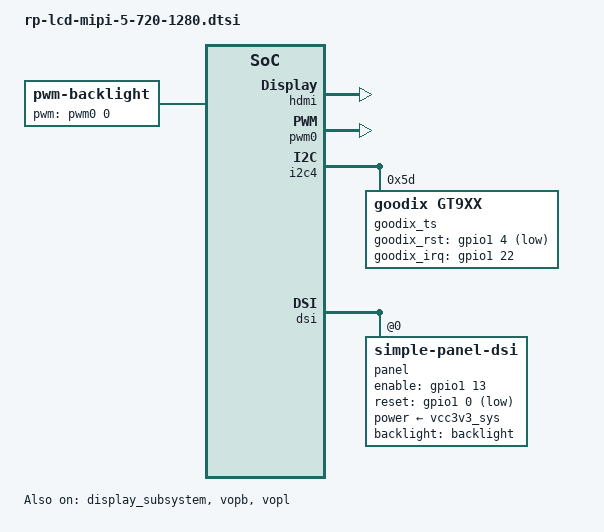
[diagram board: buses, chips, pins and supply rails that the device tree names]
/ {
	backlight: backlight {
		status = "okay";
		compatible = "pwm-backlight";
		pwms = <&pwm0 0 25000 0>;
		brightness-levels = <
			  0   1   2   3   4   5   6   7
			  8   9  10  11  12  13  14  15
			 16  17  18  19  20  21  22  23
			 24  25  26  27  28  29  30  31
			 32  33  34  35  36  37  38  39
			 40  41  42  43  44  45  46  47
			 48  49  50  51  52  53  54  55
			 56  57  58  59  60  61  62  63
			 64  65  66  67  68  69  70  71
			 72  73  74  75  76  77  78  79
			 80  81  82  83  84  85  86  87
			 88  89  90  91  92  93  94  95
			 96  97  98  99 100 101 102 103
			104 105 106 107 108 109 110 111
			112 113 114 115 116 117 118 119
			120 121 122 123 124 125 126 127
			128 129 130 131 132 133 134 135
			136 137 138 139 140 141 142 143
			144 145 146 147 148 149 150 151
			152 153 154 155 156 157 158 159
			160 161 162 163 164 165 166 167
			168 169 170 171 172 173 174 175
			176 177 178 179 180 181 182 183
			184 185 186 187 188 189 190 191
			192 193 194 195 196 197 198 199
			200 201 202 203 204 205 206 207
			208 209 210 211 212 213 214 215
			216 217 218 219 220 221 222 223
			224 225 226 227 228 229 230 231
			232 233 234 235 236 237 238 239
			240 241 242 243 244 245 246 247
			248 249 250 251 252 253 254 255>;
		default-brightness-level = <255>;
	};
};


&hdmi {
	#address-cells = <1>;
	#size-cells = <0>;
	#sound-dai-cells = <0>;
	ddc-i2c-scl-high-time-ns = <9625>;
	ddc-i2c-scl-low-time-ns = <10000>;
	status = "okay";
};

&pwm0 {
	status = "okay";
};

&i2c4 {
        status = "okay";
	goodix_ts@5d {
		compatible = "goodix,gt9xx";
		reg = <0x5d>;
		
		goodix_rst_gpio = <&gpio1 4 GPIO_ACTIVE_LOW>;
		goodix_irq_gpio = <&gpio1 22 IRQ_TYPE_EDGE_RISING>;
	
	        goodix,cfg-group0 = [
	                46 D0 02 00 05 05 35 01 01 08 1E 0F 5A 3C
	                03 05 00 00 00 00 11 11 00 19 1B 1E 14 89
	                29 0A 41 43 D3 07 00 00 00 9A 02 11 00 01
	                05 00 00 00 00 09 11 00 00 36 4A 94 45 00
	                00 00 00 00 94 37 00 8B 3B 00 83 3F 00 7C
	                43 00 76 47 00 76 10 30 48 00 F0 4A 3A FF
	                FF 27 00 00 00 00 00 00 00 00 00 00 00 00
	                00 00 00 00 00 00 00 00 00 00 00 00 00 00
	                08 0A 0C 0E 10 12 14 16 18 1A 00 00 00 00
	                00 00 00 00 00 00 00 00 00 00 00 00 00 00
	                00 00 0E 0C 0A 08 06 05 04 02 00 1D 1E 1F
	                20 22 24 28 29 2A 00 00 00 00 00 00 00 00
	                00 00 00 00 00 00 00 00 00 00 00 00 00 00
	                00 00 84 01];	
	        goodix,cfg-group1 = [
	                46 D0 02 00 05 05 35 01 01 08 1E 0F 5A 3C
	                03 05 00 00 00 00 11 11 00 19 1B 1E 14 89
	                29 0A 41 43 D3 07 00 00 00 9A 02 11 00 01
	                05 00 00 00 00 09 11 00 00 36 4A 94 45 00
	                00 00 00 00 94 37 00 8B 3B 00 83 3F 00 7C
	                43 00 76 47 00 76 10 30 48 00 F0 4A 3A FF
	                FF 27 00 00 00 00 00 00 00 00 00 00 00 00
	                00 00 00 00 00 00 00 00 00 00 00 00 00 00
	                08 0A 0C 0E 10 12 14 16 18 1A 00 00 00 00
	                00 00 00 00 00 00 00 00 00 00 00 00 00 00
	                00 00 0E 0C 0A 08 06 05 04 02 00 1D 1E 1F
	                20 22 24 28 29 2A 00 00 00 00 00 00 00 00
	                00 00 00 00 00 00 00 00 00 00 00 00 00 00
	                00 00 84 01];	
	};
};


&display_subsystem {
	status = "okay";

	ports = <&vopb_out>, <&vopl_out>;
	logo-memory-region = <&drm_logo>;

	route {
		route_hdmi: route-hdmi {
			status = "disabled";
			logo,uboot = "logo.bmp";
			logo,kernel = "logo_kernel.bmp";
			logo,mode = "fullscreen";
			charge_logo,mode = "center";
			connect = <&vopl_out_hdmi>;
		};

		route_dsi: route-dsi {
			status = "okay";
			logo,uboot = "logo.bmp";
			logo,kernel = "logo_kernel.bmp";
			logo,mode = "fullscreen";
			charge_logo,mode = "center";
			connect = <&vopb_out_dsi>;
		};

		route_dsi1: route-dsi1 {
			status = "disabled";
			logo,uboot = "logo.bmp";
			logo,kernel = "logo_kernel.bmp";
			logo,mode = "fullscreen";
			charge_logo,mode = "center";
			connect = <&vopl_out_dsi1>;
		};

		route_edp: route-edp {
			status = "disabled";
			logo,uboot = "logo.bmp";
			logo,kernel = "logo_kernel.bmp";
			logo,mode = "fullscreen";
			charge_logo,mode = "center";
			connect = <&vopb_out_edp>;
		};
	};
};

&dsi {
        status = "okay";
//	rockchip,lane-rate = <410>;

        panel {
                compatible ="simple-panel-dsi";
                status = "okay";
                reg = <0>;
		power-supply = <&vcc3v3_sys>;
                backlight = <&backlight>;
		cmd_later_reset = <0>;
                enable-gpios = <&gpio1 13 GPIO_ACTIVE_HIGH>;
		reset-gpios  = <&gpio1 0 GPIO_ACTIVE_LOW>;
                dsi,flags = <(MIPI_DSI_MODE_VIDEO | MIPI_DSI_MODE_VIDEO_BURST |
                                MIPI_DSI_MODE_VIDEO_SYNC_PULSE)>;
                dsi,format = <MIPI_DSI_FMT_RGB888>;
//		bus-format = <MEDIA_BUS_FMT_RGB666_1X24>;
                dsi,lanes = <4>;
                reset-delay-ms = <20>;
		init-delay-ms = <20>;
		enable-delay-ms = <120>;
                prepare-delay-ms = <120>;

					//for king/rp/rd board cannot enable boot logo
                                        pinctrl-names = "default";
                                        pinctrl-0 = <&pwr_en>;
               panel-init-sequence = [
			39 00 02 FE 01
			39 00 02 24 00
			39 00 02 25 53
			39 00 02 26 00
			39 00 02 27 0A
			39 00 02 29 0A
			39 00 02 2B E5
			39 00 02 16 52
			39 00 02 2F 54
			39 00 02 34 59
			39 00 02 1B 50
			39 00 02 12 02
			39 00 02 1A 06
			39 00 02 46 5F
			39 00 02 52 70
			39 00 02 53 00
			39 00 02 54 70
			39 00 02 55 00
			39 00 02 5F 13
			39 00 02 FE 03
			39 00 02 00 05
			39 00 02 01 16
			39 00 02 02 0B
			39 00 02 03 0F
			39 00 02 04 7D
			39 00 02 05 00
			39 00 02 06 50
			39 00 02 07 05
			39 00 02 08 16
			39 00 02 09 0D
			39 00 02 0A 11
			39 00 02 0B 7D
			39 00 02 0C 00
			39 00 02 0D 50
			39 00 02 0E 07
			39 00 02 0F 08
			39 00 02 10 01
			39 00 02 11 02
			39 00 02 12 00
			39 00 02 13 7D
			39 00 02 14 00
			39 00 02 15 85
			39 00 02 16 08
			39 00 02 17 03
			39 00 02 18 04
			39 00 02 19 05
			39 00 02 1A 06
			39 00 02 1B 00
			39 00 02 1C 7D
			39 00 02 1D 00
			39 00 02 1E 85
			39 00 02 1F 08
			39 00 02 20 00
			39 00 02 21 00
			39 00 02 22 00
			39 00 02 23 00
			39 00 02 24 00
			39 00 02 25 00
			39 00 02 26 00
			39 00 02 27 00
			39 00 02 28 00
			39 00 02 29 00
			39 00 02 2A 07
			39 00 02 2B 08
			39 00 02 2D 01
			39 00 02 2F 02
			39 00 02 30 00
			39 00 02 31 40
			39 00 02 32 05
			39 00 02 33 08
			39 00 02 34 54
			39 00 02 35 7D
			39 00 02 36 00
			39 00 02 37 03
			39 00 02 38 04
			39 00 02 39 05
			39 00 02 3A 06
			39 00 02 3B 00
			39 00 02 3D 40
			39 00 02 3F 05
			39 00 02 40 08
			39 00 02 41 54
			39 00 02 42 7D
			39 00 02 43 00
			39 00 02 44 00
			39 00 02 45 00
			39 00 02 46 00
			39 00 02 47 00
			39 00 02 48 00
			39 00 02 49 00
			39 00 02 4A 00
			39 00 02 4B 00
			39 00 02 4C 00
			39 00 02 4D 00
			39 00 02 4E 00
			39 00 02 4F 00
			39 00 02 50 00
			39 00 02 51 00
			39 00 02 52 00
			39 00 02 53 00
			39 00 02 54 00
			39 00 02 55 00
			39 00 02 56 00
			39 00 02 58 00
			39 00 02 59 00
			39 00 02 5A 00
			39 00 02 5B 00
			39 00 02 5C 00
			39 00 02 5D 00
			39 00 02 5E 00
			39 00 02 5F 00
			39 00 02 60 00
			39 00 02 61 00
			39 00 02 62 00
			39 00 02 63 00
			39 00 02 64 00
			39 00 02 65 00
			39 00 02 66 00
			39 00 02 67 00
			39 00 02 68 00
			39 00 02 69 00
			39 00 02 6A 00
			39 00 02 6B 00
			39 00 02 6C 00
			39 00 02 6D 00
			39 00 02 6E 00
			39 00 02 6F 00
			39 00 02 70 00
			39 00 02 71 00
			39 00 02 72 20
			39 00 02 73 00
			39 00 02 74 08
			39 00 02 75 08
			39 00 02 76 08
			39 00 02 77 08
			39 00 02 78 08
			39 00 02 79 08
			39 00 02 7A 00
			39 00 02 7B 00
			39 00 02 7C 00
			39 00 02 7D 00
			39 00 02 7E BF
			39 00 02 7F 3F
			39 00 02 80 3F
			39 00 02 81 3F
			39 00 02 82 3F
			39 00 02 83 3F
			39 00 02 84 3F
			39 00 02 85 02
			39 00 02 86 06
			39 00 02 87 3F
			39 00 02 88 14
			39 00 02 89 10
			39 00 02 8A 16
			39 00 02 8B 12
			39 00 02 8C 08
			39 00 02 8D 0C
			39 00 02 8E 0A
			39 00 02 8F 0E
			39 00 02 90 00
			39 00 02 91 04
			39 00 02 92 3F
			39 00 02 93 3F
			39 00 02 94 3F
			39 00 02 95 3F
			39 00 02 96 05
			39 00 02 97 01
			39 00 02 98 0F
			39 00 02 99 0B
			39 00 02 9A 0D
			39 00 02 9B 09
			39 00 02 9C 13
			39 00 02 9D 17
			39 00 02 9E 11
			39 00 02 9F 15
			39 00 02 A0 3F
			39 00 02 A2 07
			39 00 02 A3 03
			39 00 02 A4 3F
			39 00 02 A5 3F
			39 00 02 A6 3F
			39 00 02 A7 3F
			39 00 02 A9 3F
			39 00 02 AA 3F
			39 00 02 AB 3F
			39 00 02 AC 3F
			39 00 02 AD 3F
			39 00 02 AE 3F
			39 00 02 AF 3F
			39 00 02 B0 3F
			39 00 02 B1 3F
			39 00 02 B2 3F
			39 00 02 B3 05
			39 00 02 B4 01
			39 00 02 B5 3F
			39 00 02 B6 17
			39 00 02 B7 13
			39 00 02 B8 15
			39 00 02 B9 11
			39 00 02 BA 0F
			39 00 02 BB 0B
			39 00 02 BC 0D
			39 00 02 BD 09
			39 00 02 BE 07
			39 00 02 BF 03
			39 00 02 C0 3F
			39 00 02 C1 3F
			39 00 02 C2 3F
			39 00 02 C3 3F
			39 00 02 C4 02
			39 00 02 C5 06
			39 00 02 C6 08
			39 00 02 C7 0C
			39 00 02 C8 0A
			39 00 02 C9 0E
			39 00 02 CA 10
			39 00 02 CB 14
			39 00 02 CC 12
			39 00 02 CD 16
			39 00 02 CE 3F
			39 00 02 CF 00
			39 00 02 D0 04
			39 00 02 D1 3F
			39 00 02 D2 3F
			39 00 02 D3 3F
			39 00 02 D4 3F
			39 00 02 D5 3F
			39 00 02 D6 3F
			39 00 02 D7 3F
			39 00 02 DC 02
			39 00 02 DE 12
			39 00 02 FE 0E
			39 00 02 01 75
			39 00 02 FE 04
			39 00 02 60 00
			39 00 02 61 08
			39 00 02 62 0E
			39 00 02 63 0D
			39 00 02 64 05
			39 00 02 65 10
			39 00 02 66 0E
			39 00 02 67 0A
			39 00 02 68 16
			39 00 02 69 0C
			39 00 02 6A 10
			39 00 02 6B 07
			39 00 02 6C 0E
			39 00 02 6D 13
			39 00 02 6E 0C
			39 00 02 6F 00
			39 00 02 70 00
			39 00 02 71 08
			39 00 02 72 0E
			39 00 02 73 0D
			39 00 02 74 05
			39 00 02 75 10
			39 00 02 76 0E
			39 00 02 77 0A
			39 00 02 78 16
			39 00 02 79 0C
			39 00 02 7A 10
			39 00 02 7B 07
			39 00 02 7C 0E
			39 00 02 7D 13
			39 00 02 7E 0C
			39 78 02 7F 00
			
			39 00 02 FE 00
                        05 78 01 11
                        05 78 01 29
                ];

               panel-exit-sequence = [
                        05 00 01 28
                        05 78 01 10
                ];

                display-timings {
                        native-mode = <&timing0>;
                        timing0: timing0 {
                                clock-frequency = <60000000>;
                                hactive = <720>;
                                vactive = <1280>;
                                hback-porch = <30>;
                                hfront-porch = <64>;
                                vback-porch = <16>;
                                vfront-porch = <16>;
                                hsync-len = <4>;
                                vsync-len = <2>;
                                hsync-active = <0>;
                                vsync-active = <0>;
                                de-active = <0>;
                                pixelclk-active = <0>;
                        };
                };
        };
};

&route_dsi {
	status = "okay";
};

&vopb {
        assigned-clocks = <&cru DCLK_VOP0_DIV>;
        assigned-clock-parents = <&cru PLL_CPLL>;
        status = "okay";
};

&vopb_mmu {
        status = "okay";
};

&vopl {
        assigned-clocks = <&cru DCLK_VOP1_DIV>;
        assigned-clock-parents = <&cru PLL_VPLL>;
        status = "okay";
};

&vopl_mmu {
        status = "okay";
};

&dsi_in_vopl { 
        status = "disabled"; 
}; 
 
&hdmi_in_vopb { 
        status = "disabled"; 
}; 
 
&edp_in_vopb { 
        status = "disabled"; 
}; 
&edp_in_vopl { 
        status = "disabled"; 
}; 

&dsi1_in_vopb { 
        status = "disabled"; 
}; 
&dsi1_in_vopl { 
        status = "disabled"; 
}; 

&pinctrl{
        pwr_5v {
                        pwr_en: pwr-en {
                                rockchip,pins = //<1 13 RK_FUNC_GPIO &pcfg_pull_up>,
                                                <4 30 RK_FUNC_GPIO &pcfg_pull_up>;
                        };
        };
};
